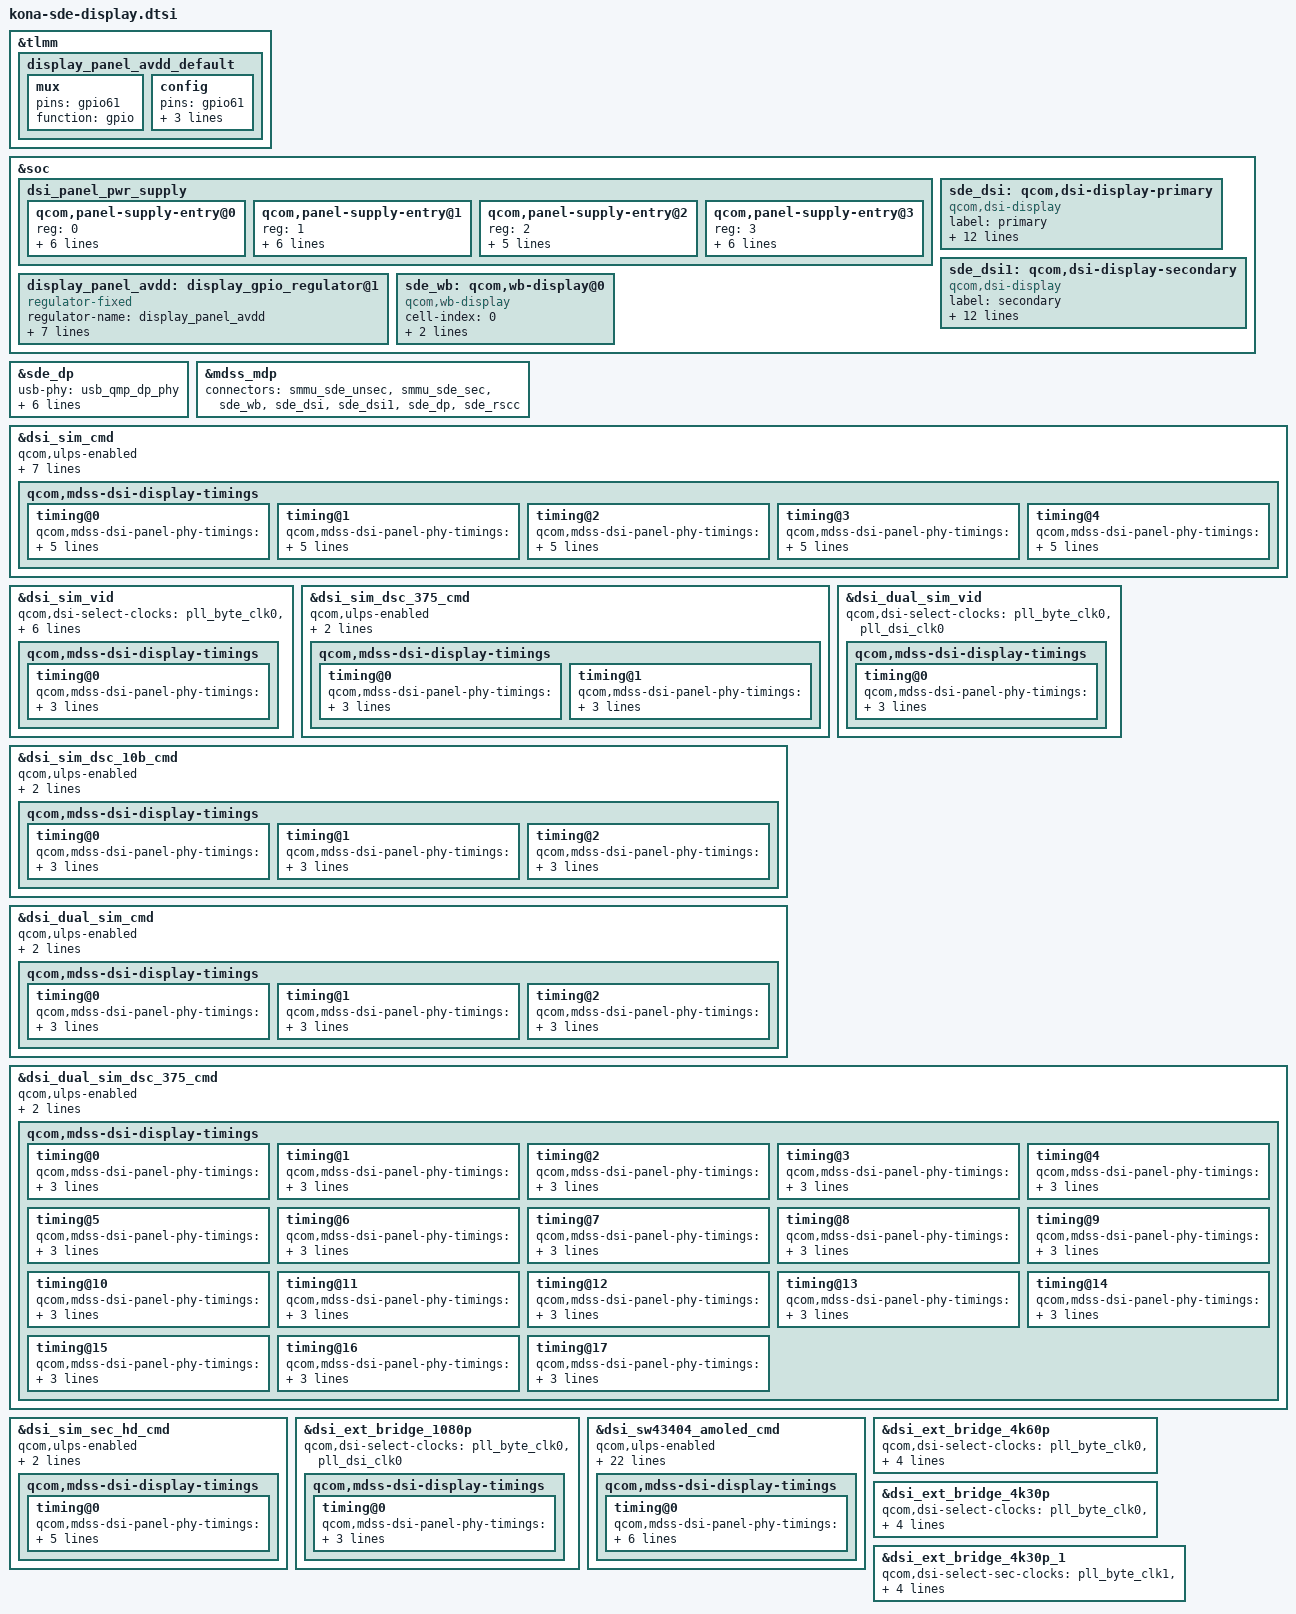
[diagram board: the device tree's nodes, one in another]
#include "dsi-panel-sw43404-amoled-dsc-wqhd-cmd.dtsi"
#include "dsi-panel-sim-cmd.dtsi"
#include "dsi-panel-sim-video.dtsi"
#include "dsi-panel-sim-dsc375-cmd.dtsi"
#include "dsi-panel-sim-dsc-10bit-cmd.dtsi"
#include "dsi-panel-sim-dualmipi-cmd.dtsi"
#include "dsi-panel-sim-dualmipi-video.dtsi"
#include "dsi-panel-sim-dualmipi-dsc375-cmd.dtsi"
#include "dsi-panel-sim-sec-hd-cmd.dtsi"
#include "dsi-panel-ext-bridge-1080p.dtsi"
#include "dsi-panel-ext-bridge-4k30p.dtsi"
#include "dsi-panel-ext-bridge-4k30p_1.dtsi"
#include "dsi-panel-ext-bridge-4k60p.dtsi"

&tlmm {
	display_panel_avdd_default: display_panel_avdd_default {
		mux {
			pins = "gpio61";
			function = "gpio";
		};

		config {
			pins = "gpio61";
			drive-strength = <8>;
			bias-disable = <0>;
			output-high;
		};
	};
};

&soc {
	dsi_panel_pwr_supply: dsi_panel_pwr_supply {
		#address-cells = <1>;
		#size-cells = <0>;

		qcom,panel-supply-entry@0 {
			reg = <0>;
			qcom,supply-name = "vddio";
			qcom,supply-min-voltage = <1800000>;
			qcom,supply-max-voltage = <1800000>;
			qcom,supply-enable-load = <62000>;
			qcom,supply-disable-load = <80>;
			qcom,supply-post-on-sleep = <20>;
		};

		qcom,panel-supply-entry@1 {
			reg = <1>;
			qcom,supply-name = "vdd";
			qcom,supply-min-voltage = <3300000>;
			qcom,supply-max-voltage = <3300000>;
			qcom,supply-enable-load = <857000>;
			qcom,supply-disable-load = <0>;
			qcom,supply-post-on-sleep = <0>;
		};

		qcom,panel-supply-entry@2 {
			reg = <2>;
			qcom,supply-name = "lab";
			qcom,supply-min-voltage = <4600000>;
			qcom,supply-max-voltage = <6000000>;
			qcom,supply-enable-load = <100000>;
			qcom,supply-disable-load = <100>;
		};

		qcom,panel-supply-entry@3 {
			reg = <3>;
			qcom,supply-name = "ibb";
			qcom,supply-min-voltage = <4600000>;
			qcom,supply-max-voltage = <6000000>;
			qcom,supply-enable-load = <100000>;
			qcom,supply-disable-load = <100>;
			qcom,supply-post-on-sleep = <20>;
		};
	};

	display_panel_avdd: display_gpio_regulator@1 {
		compatible = "regulator-fixed";
		regulator-name = "display_panel_avdd";
		regulator-min-microvolt = <5500000>;
		regulator-max-microvolt = <5500000>;
		regulator-enable-ramp-delay = <233>;
		gpio = <&tlmm 61 0>;
		enable-active-high;
		regulator-boot-on;
		pinctrl-names = "default";
		pinctrl-0 = <&display_panel_avdd_default>;
	};

	sde_dsi: qcom,dsi-display-primary {
		compatible = "qcom,dsi-display";
		label = "primary";

		qcom,dsi-ctrl = <&mdss_dsi0 &mdss_dsi1>;
		qcom,dsi-phy = <&mdss_dsi_phy0 &mdss_dsi_phy1>;

		clocks = <&mdss_dsi_phy0 0>,
			<&mdss_dsi_phy0 1>,
			<&dispcc DISP_CC_MDSS_MDP_CLK>;

		clock-names = "pll_byte_clk0", "pll_dsi_clk0",
				"mdp_core_clk";

		pinctrl-names = "panel_active", "panel_suspend";
		pinctrl-0 = <&sde_dsi_active &sde_te_active>;
		pinctrl-1 = <&sde_dsi_suspend &sde_te_suspend>;

		qcom,platform-te-gpio = <&tlmm 66 0>;
		qcom,panel-te-source = <0>;

		vddio-supply = <&pm8150_l14>;
		vdd-supply = <&pm8150a_l11>;
		avdd-supply = <&display_panel_avdd>;

		qcom,mdp = <&mdss_mdp>;
	};

	sde_dsi1: qcom,dsi-display-secondary {
		compatible = "qcom,dsi-display";
		label = "secondary";

		qcom,dsi-ctrl = <&mdss_dsi0 &mdss_dsi1>;
		qcom,dsi-phy = <&mdss_dsi_phy0 &mdss_dsi_phy1>;

		clocks = <&mdss_dsi_phy1 2>,
			<&mdss_dsi_phy1 3>,
			<&dispcc DISP_CC_MDSS_MDP_CLK>;
		clock-names = "pll_byte_clk1", "pll_dsi_clk1",
				"mdp_core_clk";

		pinctrl-names = "panel_active", "panel_suspend";
		pinctrl-0 = <&sde_dsi1_active &sde_te1_active>;
		pinctrl-1 = <&sde_dsi1_suspend &sde_te1_suspend>;

		qcom,platform-te-gpio = <&tlmm 67 0>;
		qcom,panel-te-source = <1>;

		vddio-supply = <&pm8150_l14>;
		vdd-supply = <&pm8150a_l11>;
		avdd-supply = <&display_panel_avdd>;

		qcom,mdp = <&mdss_mdp>;
	};

	sde_wb: qcom,wb-display@0 {
		compatible = "qcom,wb-display";
		cell-index = <0>;
		label = "wb_display";
		clocks = <&dispcc DISP_CC_MDSS_MDP_CLK>;
		clock-names = "mdp_core_clk";
	};
};


&sde_dp {
	usb-phy = <&usb_qmp_dp_phy>;
	qcom,dp-usbpd-detection = <&pm8150b_pdphy>;
	qcom,ext-disp = <&ext_disp>;

	usb-controller = <&usb0>;
	qcom,usbplug-cc-gpio = <&tlmm 65 0>;

	pinctrl-names = "mdss_dp_active", "mdss_dp_sleep";
	pinctrl-0 = <&sde_dp_usbplug_cc_active>;
	pinctrl-1 = <&sde_dp_usbplug_cc_suspend>;
};

&mdss_mdp {
	connectors = <&smmu_sde_unsec &smmu_sde_sec &sde_wb
			&sde_dsi &sde_dsi1 &sde_dp &sde_rscc>;
};

&dsi_sim_cmd {
	qcom,ulps-enabled;
	qcom,dsi-select-clocks = "pll_byte_clk0", "pll_dsi_clk0";
	qcom,panel-supply-entries = <&dsi_panel_pwr_supply>;
	qcom,mdss-dsi-bl-pmic-control-type = "bl_ctrl_dcs";
	qcom,platform-reset-gpio = <&tlmm 75 0>;

	qcom,mdss-dsi-display-timings {
		timing@0 {
			qcom,mdss-dsi-panel-phy-timings = [00 1c 08 07 23 22 07
				07 05 02 04 00 18 17];
			qcom,display-topology = <1 1 1>,
						<2 2 1>;
			qcom,default-topology-index = <1>;
			qcom,panel-roi-alignment = <720 40 720 40 720 40>;
			qcom,partial-update-enabled = "single_roi";
		};

		timing@1 {
			qcom,mdss-dsi-panel-phy-timings = [00 1c 08 07 23 22 07
				07 05 02 04 00 18 17];
			qcom,display-topology = <1 1 1>,
						<2 2 1>;
			qcom,default-topology-index = <1>;
			qcom,panel-roi-alignment = <720 40 720 40 720 40>;
			qcom,partial-update-enabled = "single_roi";
		};

		timing@2 {
			qcom,mdss-dsi-panel-phy-timings = [00 1c 08 07 23 22 07
				07 05 02 04 00 18 17];
			qcom,display-topology = <1 1 1>,
						<2 2 1>;
			qcom,default-topology-index = <1>;
			qcom,panel-roi-alignment = <720 40 720 40 720 40>;
			qcom,partial-update-enabled = "single_roi";
		};

		timing@3 {
			qcom,mdss-dsi-panel-phy-timings = [00 1c 08 07 23 22 07
				07 05 02 04 00 18 17];
			qcom,display-topology = <1 1 1>,
						<2 2 1>;
			qcom,default-topology-index = <1>;
			qcom,panel-roi-alignment = <540 40 540 40 540 40>;
			qcom,partial-update-enabled = "single_roi";
		};

		timing@4 {
			qcom,mdss-dsi-panel-phy-timings = [00 1c 08 07 23 22 07
				07 05 02 04 00 18 17];
			qcom,display-topology = <1 1 1>,
						<2 2 1>;
			qcom,default-topology-index = <1>;
			qcom,panel-roi-alignment = <360 40 360 40 360 40>;
			qcom,partial-update-enabled = "single_roi";
		};
	};
};

&dsi_sim_vid {
	qcom,dsi-select-clocks = "pll_byte_clk0", "pll_dsi_clk0";
	qcom,panel-supply-entries = <&dsi_panel_pwr_supply>;
	qcom,mdss-dsi-bl-pmic-control-type = "bl_ctrl_dcs";
	qcom,platform-reset-gpio = <&tlmm 75 0>;

	qcom,mdss-dsi-display-timings {
		timing@0 {
			qcom,mdss-dsi-panel-phy-timings = [00 1c 08 07 23 22 07
				07 05 02 04 00 18 17];
			qcom,display-topology = <1 0 1>,
						<2 0 1>;
			qcom,default-topology-index = <0>;
		};
	};
};

&dsi_sim_dsc_375_cmd {
	qcom,ulps-enabled;
	qcom,dsi-select-clocks = "pll_byte_clk0", "pll_dsi_clk0";
	qcom,mdss-dsi-display-timings {
		timing@0 { /* 1080p */
			qcom,mdss-dsi-panel-phy-timings = [00 1c 08 07 23 22 07
				07 05 02 04 00 18 17];
			qcom,display-topology = <1 1 1>;
			qcom,default-topology-index = <0>;
		};

		timing@1 { /* qhd */
			qcom,mdss-dsi-panel-phy-timings = [00 1e 08 07 24 22 08
				08 05 02 04 00 19 18];
			qcom,display-topology = <1 1 1>,
						<2 2 1>, /* dsc merge */
						<2 1 1>; /* 3d mux */
			qcom,default-topology-index = <0>;
		};
	};
};

&dsi_sim_dsc_10b_cmd {
	qcom,ulps-enabled;
	qcom,dsi-select-clocks = "pll_byte_clk0", "pll_dsi_clk0";
	qcom,mdss-dsi-display-timings {
		timing@0 { /* QHD 60fps */
			qcom,mdss-dsi-panel-phy-timings = [00 1c 08 07 23 22 07
				07 05 02 04 00 18 17];
			qcom,display-topology = <1 1 1>;
			qcom,default-topology-index = <0>;
		};

		timing@1 { /* 1080 60fps */
			qcom,mdss-dsi-panel-phy-timings = [00 1e 08 07 24 22 08
				08 05 02 04 00 19 18];
			qcom,display-topology = <1 1 1>,
						<2 2 1>, /* dsc merge */
						<2 1 1>; /* 3d mux */
			qcom,default-topology-index = <0>;
		};

		timing@2 { /* QHD 90fps */
			qcom,mdss-dsi-panel-phy-timings = [00 1c 08 07 23 22 07
				07 05 02 04 00 18 17];
			qcom,display-topology = <1 1 1>;
			qcom,default-topology-index = <0>;
		};
	};
};

&dsi_dual_sim_cmd {
	qcom,ulps-enabled;
	qcom,dsi-select-clocks = "pll_byte_clk0", "pll_dsi_clk0";
	qcom,mdss-dsi-display-timings {
		timing@0 {
			qcom,mdss-dsi-panel-phy-timings = [00 24 09 09 26 24 09
				09 06 02 04 00 18 17];
			qcom,display-topology = <2 0 2>;
			qcom,default-topology-index = <0>;
		};

		timing@1 {
			qcom,mdss-dsi-panel-phy-timings = [00 1c 08 07 23 22 07
				07 05 02 04 00 18 17];
			qcom,display-topology = <2 0 2>,
						<1 0 2>;
			qcom,default-topology-index = <0>;
		};

		timing@2 {
			qcom,mdss-dsi-panel-phy-timings = [00 1e 08 07 24 22 08
				08 05 02 04 00 19 18];
			qcom,display-topology = <2 0 2>;
			qcom,default-topology-index = <0>;
		};
	};
};

&dsi_dual_sim_vid {
	qcom,dsi-select-clocks = "pll_byte_clk0", "pll_dsi_clk0";
	qcom,mdss-dsi-display-timings {
		timing@0 {
			qcom,mdss-dsi-panel-phy-timings = [00 1c 08 07 23 22 07
				07 05 02 04 00 18 17];
			qcom,display-topology = <2 0 2>,
						<1 0 2>;
			qcom,default-topology-index = <0>;
		};
	};
};

&dsi_dual_sim_dsc_375_cmd {
	qcom,ulps-enabled;
	qcom,dsi-select-clocks = "pll_byte_clk0", "pll_dsi_clk0";
	qcom,mdss-dsi-display-timings {
		timing@0 { /* 4k  30 FPS*/
			qcom,mdss-dsi-panel-phy-timings = [00 0e 03 03 1e 1d 04
				04 02 02 04 00 0e 13];
			qcom,display-topology = <2 2 2>;
			qcom,default-topology-index = <0>;
		};

		timing@1 { /* 4k  60 FPS*/
			qcom,mdss-dsi-panel-phy-timings = [00 18 06 06 21 20 06
				06 04 02 04 00 15 16];
			qcom,display-topology = <2 2 2>;
			qcom,default-topology-index = <0>;
		};

		timing@2 { /* 4k  90 FPS*/
			qcom,mdss-dsi-panel-phy-timings = [00 22 09 09 25 23 09
				09 06 02 04 00 1c 19];
			qcom,display-topology = <2 2 2>;
			qcom,default-topology-index = <0>;
		};

		timing@3 { /* 4k  120 FPS*/
			qcom,mdss-dsi-panel-phy-timings = [00 2c 0c 0c 29 27 0c
				0c 08 02 04 00 24 1b];
			qcom,display-topology = <2 2 2>;
			qcom,default-topology-index = <0>;
		};

		timing@4 { /* 1080  30 FPS*/
			qcom,mdss-dsi-panel-phy-timings = [01 09 01 01 1b 1b 01
				01 01 02 04 00 0a 11];
			qcom,display-topology = <2 2 2>;
			qcom,default-topology-index = <0>;
		};

		timing@5 { /* 1080  60 FPS*/
			qcom,mdss-dsi-panel-phy-timings = [00 0b 02 02 1c 1c 03
				02 01 02 04 00 0c 12];
			qcom,display-topology = <2 2 2>;
			qcom,default-topology-index = <0>;
		};

		timing@6 { /* 1080  90 FPS*/
			qcom,mdss-dsi-panel-phy-timings = [00 0e 03 03 1e 1d 04
				03 02 02 04 00 0e 13];
			qcom,display-topology = <2 2 2>;
			qcom,default-topology-index = <0>;
		};

		timing@7 { /* 1080  120 FPS*/
			qcom,mdss-dsi-panel-phy-timings = [00 11 04 04 1e 1e 04
				04 02 02 04 00 10 14];
			qcom,display-topology = <2 2 2>;
			qcom,default-topology-index = <0>;
		};

		timing@8 { /* qhd 30 FPS*/
			qcom,mdss-dsi-panel-phy-timings = [00 0a 02 02 1c 1c 02
				02 01 02 04 00 0b 12];
			qcom,display-topology = <2 2 2>;
			qcom,default-topology-index = <0>;
		};

		timing@9 { /* qhd 60 FPS*/
			qcom,mdss-dsi-panel-phy-timings = [00 0f 03 03 1e 1d 04
				04 02 02 04 00 0f 13];
			qcom,display-topology = <2 2 2>;
			qcom,default-topology-index = <0>;
		};

		timing@10 { /* qhd  90 FPS*/
			qcom,mdss-dsi-panel-phy-timings = [00 14 05 05 1f 1f 05
				05 03 02 04 00 12 15];
			qcom,display-topology = <2 2 2>;
			qcom,default-topology-index = <0>;
		};

		timing@11 { /* qhd 120 FPS*/
			qcom,mdss-dsi-panel-phy-timings = [00 19 06 06 21 20 07
				06 04 02 04 00 15 16];
			qcom,display-topology = <2 2 2>;
			qcom,default-topology-index = <0>;
		};

		timing@12 { /* 5k */
			qcom,mdss-dsi-panel-phy-timings = [00 1a 07 06 22 21 07
				07 04 02 04 00 16 16];
			qcom,display-topology = <2 2 2>;
			qcom,default-topology-index = <0>;
		};

		timing@13 { /* 720p 30 FPS */
			qcom,mdss-dsi-panel-phy-timings = [03 07 00 01 1a 1a 01
				01 00 02 04 00 08 11];
			qcom,display-topology = <2 2 2>;
			qcom,default-topology-index = <0>;
		};

		timing@14 { /* 720p 60 FPS */
			qcom,mdss-dsi-panel-phy-timings = [01 09 01 01 1b 1b 01
				01 01 02 04 00 0a 11];
			qcom,display-topology = <2 2 2>;
			qcom,default-topology-index = <0>;
		};

		timing@15 { /* 720p 90 FPS */
			qcom,mdss-dsi-panel-phy-timings = [00 0a 02 02 1c 1c 02
				02 01 02 04 00 0b 12];
			qcom,display-topology = <2 2 2>;
			qcom,default-topology-index = <0>;
		};

		timing@16 { /* 720 120 FPS */
			qcom,mdss-dsi-panel-phy-timings = [00 0b 02 02 1c 1c 03
				03 01 02 04 00 0c 12];
			qcom,display-topology = <2 2 2>;
			qcom,default-topology-index = <0>;
		};

		timing@17 { /* 1080 144 FPS */
			qcom,mdss-dsi-panel-phy-timings = [00 13 05 04 1f 1e 05
				05 03 02 04 00 12 14];
			qcom,display-topology = <2 2 2>;
			qcom,default-topology-index = <0>;
		};

	};
};

&dsi_sim_sec_hd_cmd {
	qcom,ulps-enabled;
	qcom,dsi-select-sec-clocks = "pll_byte_clk1", "pll_dsi_clk1";
	qcom,mdss-dsi-display-timings {
		timing@0 {
			qcom,mdss-dsi-panel-phy-timings = [00 1e 08 07 24 22
				08 08 05 02 04 00 19 17];
			qcom,display-topology = <1 0 1>;
			qcom,default-topology-index = <0>;
			qcom,panel-roi-alignment = <720 40 720 40 720 40>;
			qcom,partial-update-enabled = "single_roi";
		};
	};
};

&dsi_ext_bridge_1080p {
	qcom,dsi-select-clocks = "pll_byte_clk0", "pll_dsi_clk0";
	qcom,mdss-dsi-display-timings {
		timing@0 {
			qcom,mdss-dsi-panel-phy-timings = [00 1e 08 07 24 22 08
				08 05 02 04 00 19 17];
			qcom,display-topology = <1 0 1>;
			qcom,default-topology-index = <0>;
		};
	};
};

&dsi_sw43404_amoled_cmd {
	qcom,ulps-enabled;
	qcom,esd-check-enabled;
	qcom,mdss-dsi-panel-status-check-mode = "reg_read";
	qcom,mdss-dsi-panel-status-command = [06 01 00 01 00 00 01 0a];
	qcom,mdss-dsi-panel-status-command-state = "dsi_lp_mode";
	qcom,mdss-dsi-panel-status-value = <0x9c>;
	qcom,mdss-dsi-panel-status-read-length = <1>;

	qcom,panel-supply-entries = <&dsi_panel_pwr_supply>;
	qcom,mdss-dsi-bl-pmic-control-type = "bl_ctrl_dcs";
	qcom,mdss-dsi-bl-min-level = <1>;
	qcom,mdss-dsi-bl-max-level = <1023>;
	qcom,mdss-brightness-max-level = <255>;
	qcom,platform-te-gpio = <&tlmm 66 0>;
	qcom,platform-reset-gpio = <&tlmm 75 0>;
	qcom,mdss-dsi-panel-test-pin = <&tlmm 46 0>;

	qcom,dsi-select-clocks = "pll_byte_clk0", "pll_dsi_clk0",
		"src_byte_clk0", "src_pixel_clk0",
		"shadow_byte_clk0", "shadow_pixel_clk0";

	qcom,mdss-dsi-display-timings {
		timing@0 {
			qcom,mdss-dsi-panel-phy-timings = [00 14 05 05 1f 1e 05
				05 03 02 04 00 12 15];
			qcom,display-topology = <2 2 1>;
			qcom,default-topology-index = <0>;
			qcom,partial-update-enabled = "single_roi";
			qcom,panel-roi-alignment = <720 180 180 180 1440 180>;
		};
	};
};

&dsi_ext_bridge_4k60p {
	qcom,dsi-select-clocks = "pll_byte_clk0", "pll_dsi_clk0";
	qcom,mdss-dsi-ext-bridge-hpd;
	qcom,mdss-dsi-ext-bridge-dynamic-mode-set;
	qcom,mdss-dsi-ext-bridge-custom-topology;
};

&dsi_ext_bridge_4k30p {
	qcom,dsi-select-clocks = "pll_byte_clk0", "pll_dsi_clk0";
	qcom,mdss-dsi-ext-bridge-hpd;
	qcom,mdss-dsi-ext-bridge-dynamic-mode-set;
	qcom,mdss-dsi-ext-bridge-custom-topology;
};

&dsi_ext_bridge_4k30p_1 {
	qcom,dsi-select-sec-clocks = "pll_byte_clk1", "pll_dsi_clk1";
	qcom,mdss-dsi-ext-bridge-hpd;
	qcom,mdss-dsi-ext-bridge-dynamic-mode-set;
	qcom,mdss-dsi-ext-bridge-custom-topology;
};
